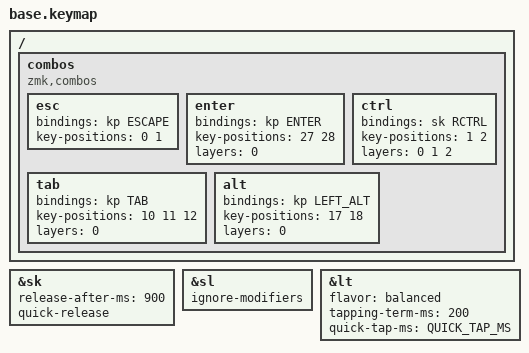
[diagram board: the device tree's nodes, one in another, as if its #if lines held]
#include <behaviors.dtsi>
#include <behaviors/num_word.dtsi> // Requires zmk-auto-layer module.
#include <behaviors/unicode.dtsi> // Requires zmk-unicode module.
#include <zmk-helpers/helper.h> // Requires zmk-helpers module.
#include <dt-bindings/zmk/keys.h>
#ifdef CONFIG_WIRELESS
  #include <dt-bindings/zmk/bt.h>
  #include <dt-bindings/zmk/outputs.h>
  #define _BT_SEL_KEYS_                                                        \
      &bt BT_SEL 0 &bt BT_SEL 1 &bt BT_SEL 2 &bt BT_SEL 3 &bt BT_CLR
#else
  #define _BT_SEL_KEYS_ &trans &trans &trans &trans &trans
#endif

#define DEF 0
#define NAV 1
#define FN 2
#define NUM 3
#define SYS 4

#define XXX &none
#define ___ &trans

/* Global defaults */

#define QUICK_TAP_MS 175

&sk {
  release-after-ms = <900>;
  quick-release;
};

&sl { // Allow sticky mods to chord across sticky layers.
  ignore-modifiers;
};

&lt {
  flavor = "balanced";
  tapping-term-ms = <200>;
  quick-tap-ms = <QUICK_TAP_MS>;
};

/ {
    combos {
        compatible = "zmk,combos";
       esc {
            bindings = <&kp ESCAPE>;
            key-positions = <0 1>;
        };

        enter {
            bindings = <&kp ENTER>;
            key-positions = <27 28>;
            layers = <0>;
        };

        ctrl {
            bindings = <&sk RCTRL>;
            key-positions = <1 2>;
            layers = <0 1 2>;
        };

        tab {
            bindings = <&kp TAB>;
            key-positions = <10 11 12>;
            layers = <0>;
        };

        alt {
            bindings = <&kp LEFT_ALT>;
            key-positions = <17 18>;
            layers = <0>;
        };
    };
};

/* Homerow mods */

#define KEYS_L LT0 LT1 LT2 LT3 LT4 LM0 LM1 LM2 LM3 LM4 LB0 LB1 LB2 LB3 LB4
#define KEYS_R RT0 RT1 RT2 RT3 RT4 RM0 RM1 RM2 RM3 RM4 RB0 RB1 RB2 RB3 RB4
#ifndef LH2
  #define THUMBS LH1 LH0 RH0 RH1         // Thumbs on 34 keys.
#else
  #define THUMBS LH2 LH1 LH0 RH0 RH1 RH2 // Thumbs on 36+ keys.
#endif

// #include "combos.dtsi" // Must be sourced after HRM-combo hack.
#include "leader.dtsi"
#include "mouse.dtsi"

/* Keymap */

// ZMK_CONDITIONAL_LAYER(sys, FN NUM, SYS) // FN + NUM --> SYS.

#ifndef ZMK_BASE_LAYER
  #define ZMK_BASE_LAYER(name, LT, RT, LM, RM, LB, RB, LH, RH)                 \
      ZMK_LAYER(name, LT RT LM RM LB RB LH RH)
#endif

ZMK_BASE_LAYER(Default,
&kp Q  &kp W  &kp E     &kp R      &kp T  ,  &kp Y  &kp U            &kp I      &kp O    &kp P   ,
&kp A  &kp S  &kp D     &kp F      &kp G  ,  &kp H  &kp J            &kp K      &kp L    &kp SQT  ,
&kp Z  &kp X  &kp C     &kp V      &kp B  ,  &kp N  &kp M            &kp COMMA  &kp DOT  &kp BSPC ,
                      &kp LGUI  &kp SPACE  &mo 1 ,   &mo 2  &kp RIGHT_SHIFT  &tog 4
)

ZMK_BASE_LAYER(Number,
&kp Q  &kp W   &kp N7  &kp N8  &kp N9  ,  &kp LS(LPAR)  &kp LS(RPAR)  &kp MINUS        &kp EQUAL     &kp BSLH ,
&kp A  &kp N4  &kp N4  &kp N5  &kp N6  ,  &kp LBKT      &kp RBKT      &kp LS(UNDER)    &kp LS(PLUS)  &kp SEMI , 
&kp Z  &kp N0  &kp N1  &kp N2  &kp N3  ,  &kp LS(LBRC)  &kp LS(RBRC)  &trans           &trans        &kp FSLH  ,
                       &trans  &trans  &trans    &mo 3    ,     &kp LSHFT     &kp PRINTSCREEN
)

ZMK_BASE_LAYER(Navigation,
&kp GRAVE  &kp F12  &kp F7  &kp F8  &kp F9  ,  &kp LC(A)     &kp LC(C)     &kp LC(V)  &kp HOME   &kp PG_UP ,
&trans     &kp F11  &kp F4  &kp F5  &kp F6  ,  &kp C_VOL_DN  &kp C_VOL_UP  &kp UP     &kp END    &kp PG_DN ,
&trans     &kp F10  &kp F1  &kp F2  &kp F3  ,  &kp CAPS      &kp LEFT      &kp DOWN   &kp RIGHT  &kp DEL,
                            &trans  &trans  &trans  ,  &trans        &trans        &trans
)

ZMK_BASE_LAYER(Bluetooth,
&trans  &trans  &trans  &trans  &trans  ,  &bt BT_SEL 0  &bt BT_SEL 1  &bt BT_SEL 2  &bt BT_SEL 3  &bt BT_CLR  ,
&trans  &trans  &trans  &trans  &trans  ,  &trans        &trans        &trans        &trans        &trans      ,
&trans  &trans  &trans  &trans  &trans  ,  &trans        &trans        &trans        &trans        &trans     ,
                        &trans  &trans  &trans ,   &trans        &trans        &trans
)

ZMK_BASE_LAYER(Mouse,
&trans  &trans  &trans  &trans  &trans  ,  &trans  &trans          &mkp MCLK       &kp LC(MINUS)    &kp LC(EQUAL)   ,   
&trans  &trans  &trans  &trans  &trans  ,  &trans  &mkp LCLK       U_MS_U    &mkp RCLK        U_WH_U  ,
&trans  &trans  &trans  &trans  &trans  ,  &trans  U_MS_L  U_MS_D  U_MS_R  U_WH_D  ,
                        &trans  &trans  &trans  ,  &trans  &trans          &trans
)

/* vim: set ft=c tw=146: */
